# S6E2G2xJ register map
Vendor: Spansion; File version: 2.0
CPU: CM4 r0p1, little endian, MPU, FPU, 4 interrupt priority bits
Registers are 32-bit, read-write, reset 0x0 unless marked. A register's access mark holds for its fields unless they carry their own. Offsets are from the block's base; [hi:lo] are bit positions; {n}, {i} and the like mark numbered series.

## CRTRIM — CR Trimming Registers
Base 0x4002E000
0x00 MCR_PSR 8-bit reset 0x1 — High-speed CR oscillation Frequency Division Setup Register
  [2:0] CSR — High-speed CR oscillation frequency division ratio setting bits
0x04 MCR_FTRM reset 0x1EF — High-speed CR oscillation Frequency Trimming Register
  [9:0] TRD — Frequency trimming setup bits
0x08 MCR_TTRM reset 0x10 — High-speed CR oscillation Temperature Trimming Register
  [4:0] TRT — Temperature trimming setup bits
0x0C MCR_RLR reset 0x1 — High-Speed CR Oscillation Register Write-Protect Register
  [31:0] TRMLCK — Register write-protect bits

## EXTI — External Interrupt and NMI Control
Base 0x40030000
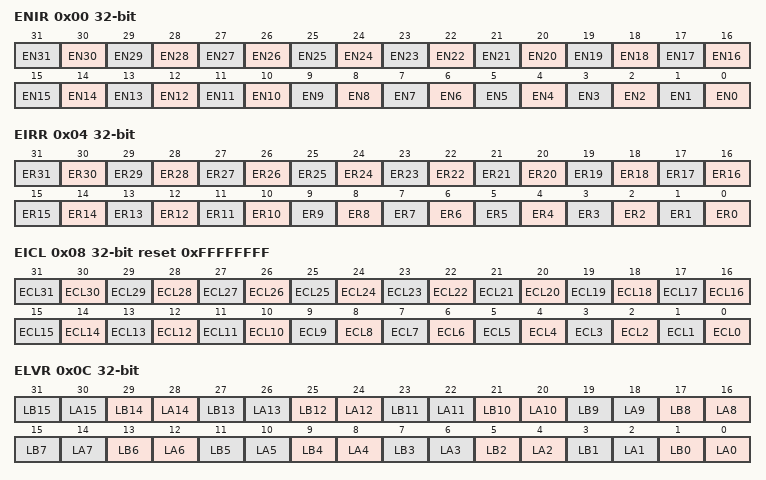
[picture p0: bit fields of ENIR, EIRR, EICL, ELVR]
0x00 ENIR — Enable Interrupt Request Register
  [n] EN{n} (n=0..31) — Bit{n} of ENIR
0x04 EIRR ro reset not defined — External Interrupt Request Register
  [n] ER{n} (n=0..31) — Bit{n} of EIRR
0x08 EICL reset 0xFFFFFFFF — External Interrupt Clear Register
  [n] ECL{n} (n=0..31) — Bit{n} of EICL
0x0C ELVR — External Interrupt Level Register
  [2n+1] LB{n} (n=0..15) — Bit{2n+1} of ELVR
  [2n] LA{n} (n=0..15) — Bit{2n} of ELVR
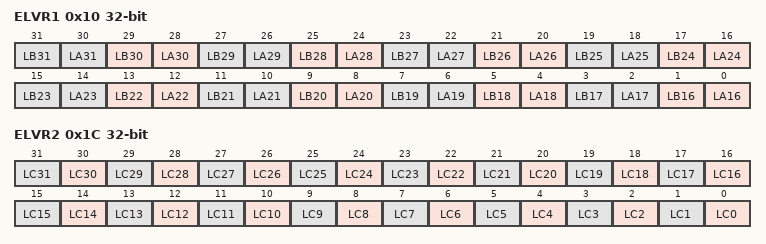
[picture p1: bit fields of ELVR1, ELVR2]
0x10 ELVR1 — External Interrupt Level Register 1
  [2n-31] LB{n} (n=16..31) — Bit{2n-31} of ELVR1
  [2n-32] LA{n} (n=16..31) — Bit{2n-32} of ELVR1
0x14 NMIRR 16-bit ro — Non Maskable Interrupt Request Register
  [0] NR — NMI interrupt request detection bit
0x18 NMICL 16-bit reset 0x1 — Non Maskable Interrupt Clear Register
  [0] NCL — NMI interrupt cause clear bit
0x1C ELVR2 — External Interrupt Factor Level Register 2
  [n] LC{n} (n=0..31) — Bit{n} of External interrupt request detection level selection bits

## LVD — Low-voltage Detection
Base 0x40035000
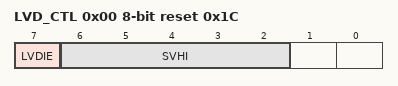
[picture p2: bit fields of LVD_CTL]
0x00 LVD_CTL 8-bit reset 0x1C — Low-voltage Detection Voltage Control Register
  [7] LVDIE — Low-voltage detection interrupt enable bit
  [6:2] SVHI — Low-voltage detection interrupt voltage setting bits
0x04 LVD_STR 8-bit ro — Low-voltage Detection Interrupt Factor Register
  [7] LVDIR — Low-voltage detection interrupt factor bit
0x08 LVD_CLR 8-bit reset 0x80 — Low-voltage Detection Interrupt Factor Clear Register
  [7] LVDCL — Low-voltage detection interrupt factor clear bit
0x0C LVD_RLR reset 0x1 — Low-voltage Detection Voltage Protection Register
  [31:0] LVDLCK — Low-voltage Detection Voltage Control Register protection bits
0x10 LVD_STR2 8-bit ro — Low-voltage Detection Circuit Status Register
  [7] LVDIRDY — Low-voltage detection interrupt status flag

## DS — Low Power Consumption Mode
Base 0x40035100
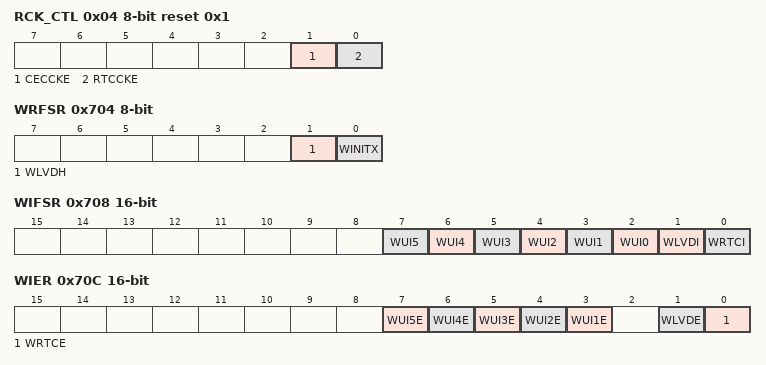
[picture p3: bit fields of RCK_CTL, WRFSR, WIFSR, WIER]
0x04 RCK_CTL 8-bit reset 0x1 — Sub Clock Control Register
  [1] CECCKE — CEC clock control bit
  [0] RTCCKE — RTC clock control bit
0x700 PMD_CTL 8-bit — RTC Mode Control Register
  [0] RTCE — RTC mode control bit
0x704 WRFSR 8-bit ro — Deep Standby Return Cause Register 1
  [1] WLVDH — Low-voltage detection reset return bit
  [0] WINITX — INITX pin input reset return bit
0x708 WIFSR 16-bit ro — Deep Standby Return Cause Register 2
  [n+2] WUI{n} (n=0..5) — WKUP pin input return bit {n}
  [1] WLVDI — LVD interrupt return bit
  [0] WRTCI — RTC interrupt return bit
0x70C WIER 16-bit — Deep Standby Return Enable Register
  [n+2] WUI{n}E (n=1..5) — WKUP pin input return enable bit {n}
  [1] WLVDE — LVD interrupt return enable bit
  [0] WRTCE — RTC interrupt return enable bit
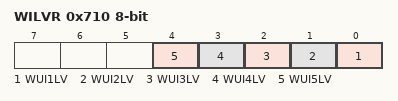
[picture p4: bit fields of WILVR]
0x710 WILVR 8-bit — WKUP Pin Input Level Register
  [n-1] WUI{n}LV (n=1..5) — WKUP pin input level select bit {n}
0x714 DSRAMR 8-bit — Deep Standby RAM Retention Register
  [1:0] SRAMR — On-chip SRAM retention control bits
{0x7FF+i} BUR{i:02} 8-bit (i=1..16) — Backup Registers from {i}

## USBETHERCLK — USB/Ethernet Clock
Base 0x40036000
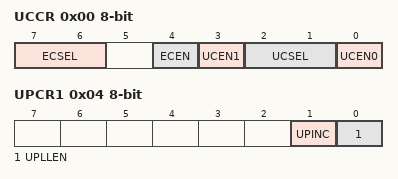
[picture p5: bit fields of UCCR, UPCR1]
0x00 UCCR 8-bit (reset mask 0x7F) — USB/Ethernet-PLL Clock Control Register
  [7:6] ECSEL — Ethernet clock selection bit
  [4] ECEN — Ethernet clock output enable bit
  [3] UCEN1 — USB1 clock output enable bit
  [2:1] UCSEL — USB1/0 clock selection bit
  [0] UCEN0 — USB0 clock output enable bit
0x04 UPCR1 8-bit — USB/Ethernet-PLL Control Register 1
  [1] UPINC — USB/Ethernet-PLL input clock selection bit
  [0] UPLLEN — USB/Ethernet-PLL oscillation enable bit
0x08 UPCR2 8-bit — USB/Ethernet-PLL Control Register 2
  [2:0] UPOWT — USB/Ethernet-PLL oscillation stabilization wait time setting bit
0x0C UPCR3 8-bit — USB/Ethernet-PLL Control Register 3
  [4:0] UPLLK — Frequency division ratio (K) setting bit of the USB/Ethernet-PLL clock
0x10 UPCR4 8-bit reset 0x3B — USB/Ethernet-PLL Control Register 4
  [6:0] UPLLN — Frequency division ratio (N) setting bit of the USB/Ethernet-PLL clock
0x14 UP_STR 8-bit ro — USB/Ethernet-PLL Status Register
  [0] UPRDY — USB/Ethernet-PLL oscillation stabilization bit
0x18 UPINT_ENR 8-bit — USB/Ethernet-PLL Interrupt Source Enable Register
  [0] UPCSE — USB/Ethernet-PLL oscillation stabilization wait complete interrupt enable bit
0x1C UPINT_CLR 8-bit wo — USB/Ethernet-PLL Interrupt Source Clear Register
  [0] UPCSC — USB/Ethernet-PLL oscillation stabilization interrupt source clear bit
0x20 UPINT_STR 8-bit ro — USB/Ethernet-PLL Interrupt Source Status Register
  [0] UPCSI — USB/Ethernet-PLL interrupt source status bit
0x24 UPCR5 8-bit reset 0x4 — USB/Ethernet-PLL Control Register 5
  [3:0] UPLLM — Frequency division ratio (M) setting bit of the USB/Ethernet-PLL clock
0x28 UPCR6 8-bit reset 0x2 — USB/Ethernet-PLL Setting Register 6
  [3:0] UBSR — CLKPLL division ratio setting bit
0x2C UPCR7 8-bit — USB/Ethernet-PLL Setting Register 7
  [0] EPLLEN — USB/Ethernet-PLL control bit in Timer mode
0x30 USBEN0 8-bit — USB0 Enable Register
  [0] USBEN0 — USB0 enable bit
0x34 USBEN1 8-bit — USB1 Enable Register
  [0] USBEN1 — USB1 enable bit

## Notices in the file
Copyright (C) 2015 Spansion LLC. All Rights Reserved.
This software is owned and published by:
Spansion LLC, 915 DeGuigne Dr. Sunnyvale, CA  94088-3453 ("Spansion").
BY DOWNLOADING, INSTALLING OR USING THIS SOFTWARE, YOU AGREE TO BE BOUND
BY ALL THE TERMS AND CONDITIONS OF THIS AGREEMENT.
This software contains source code for use with Spansion
components. This software is licensed by Spansion to be adapted only
for use in systems utilizing Spansion components. Spansion shall not be
responsible for misuse or illegal use of this software for devices not
supported herein.  Spansion is providing this software "AS IS" and will
not be responsible for issues arising from incorrect user implementation
of the software.
SPANSION MAKES NO WARRANTY, EXPRESS OR IMPLIED, ARISING BY LAW OR OTHERWISE,
REGARDING THE SOFTWARE (INCLUDING ANY ACOOMPANYING WRITTEN MATERIALS),
ITS PERFORMANCE OR SUITABILITY FOR YOUR INTENDED USE, INCLUDING,
WITHOUT LIMITATION, THE IMPLIED WARRANTY OF MERCHANTABILITY, THE IMPLIED
WARRANTY OF FITNESS FOR A PARTICULAR PURPOSE OR USE, AND THE IMPLIED
WARRANTY OF NONINFRINGEMENT.
SPANSION SHALL HAVE NO LIABILITY (WHETHER IN CONTRACT, WARRANTY, TORT,
NEGLIGENCE OR OTHERWISE) FOR ANY DAMAGES WHATSOEVER (INCLUDING, WITHOUT
LIMITATION, DAMAGES FOR LOSS OF BUSINESS PROFITS, BUSINESS INTERRUPTION,
LOSS OF BUSINESS INFORMATION, OR OTHER PECUNIARY LOSS) ARISING FROM USE OR
INABILITY TO USE THE SOFTWARE, INCLUDING, WITHOUT LIMITATION, ANY DIRECT,
INDIRECT, INCIDENTAL, SPECIAL OR CONSEQUENTIAL DAMAGES OR LOSS OF DATA,
SAVINGS OR PROFITS,
EVEN IF SPANSION HAS BEEN ADVISED OF THE POSSIBILITY OF SUCH DAMAGES.
YOU ASSUME ALL RESPONSIBILITIES FOR SELECTION OF THE SOFTWARE TO ACHIEVE YOUR
INTENDED RESULTS, AND FOR THE INSTALLATION OF, USE OF, AND RESULTS OBTAINED
FROM, THE SOFTWARE.
This software may be replicated in part or whole for the licensed use,
with the restriction that this Disclaimer and Copyright notice must be
included with each copy of this software, whether used in part or whole,
at all times.
